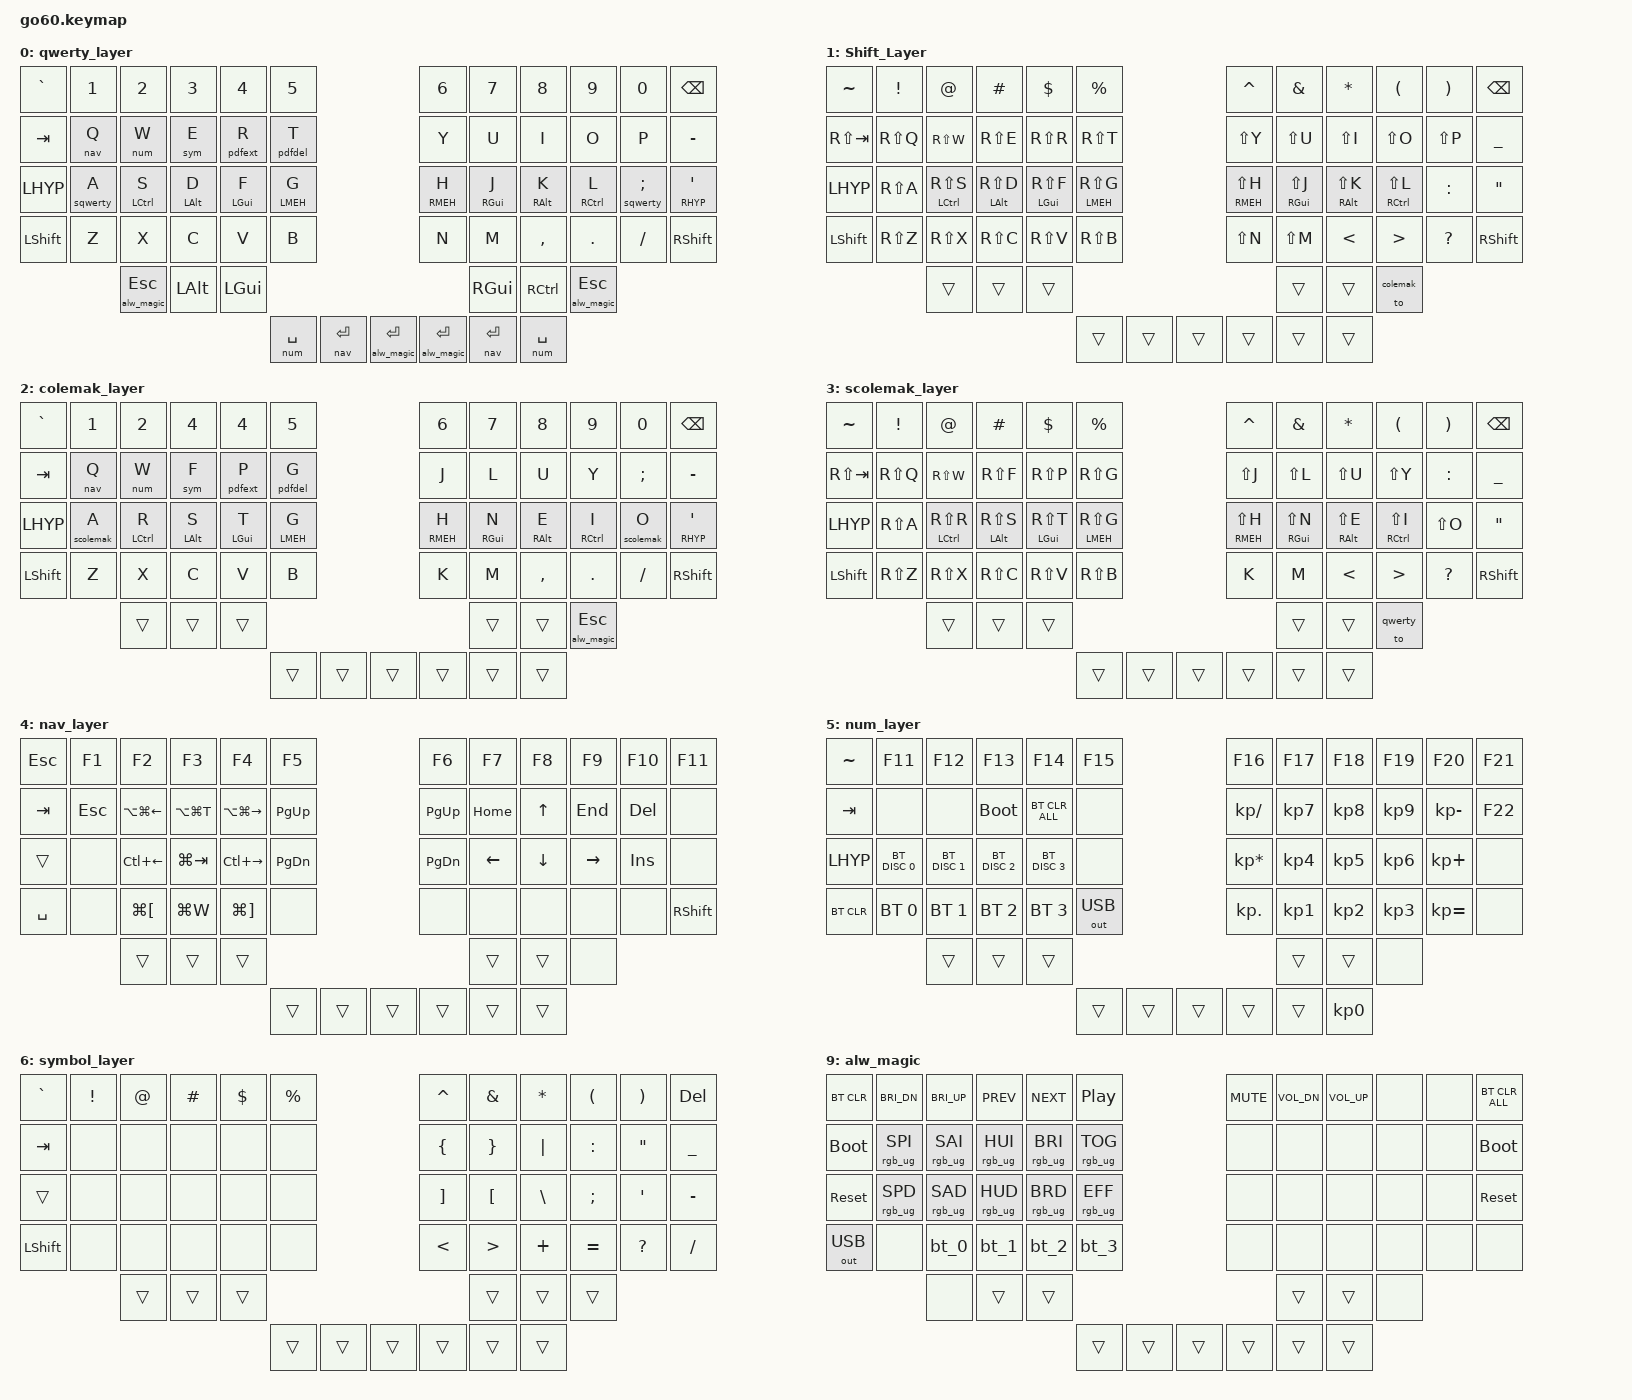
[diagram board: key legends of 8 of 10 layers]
/*
 * Copyright (c) 2020 The ZMK Contributors
 *
 * SPDX-License-Identifier: MIT
 */

#include <behaviors.dtsi>

#include <dt-bindings/zmk/bt.h>
#include <dt-bindings/zmk/ext_power.h>
#include <dt-bindings/zmk/keys.h>
#include <dt-bindings/zmk/outputs.h>
#include <dt-bindings/zmk/rgb.h>
#include <dt-bindings/zmk/input_transform.h>
#include <dt-bindings/zmk/pointing.h>

#include <input/processors.dtsi>
#include <zephyr/dt-bindings/input/input-event-codes.h>

// layers
#define LAYER_Base 9
#define LAYER_Keypad 10
#define LAYER_SymbolNav 11
#define LAYER_Magic 12
#define LAYER_Factory 0

//Layer Names Defines
#define qwerty 0
#define sqwerty 1
#define colemak 2
#define scolemak 3
#define nav 4
#define num 5
#define sym 6
#define pdfext 7
#define pdfdel 8
#define alw_magic 9



// custom modifier combinations
#define LHYP LS(LC(LA(LGUI)))
#define RHYP RS(RC(RA(RGUI)))
#define LMEH LS(LC(LALT))
#define RMEH RS(RC(RALT))

/ {
    combos {
        compatible = "zmk,combos";

        combo_tl1 {
            timeout-ms = <200>;
            key-positions = <36 37>;
            bindings = <&tog colemak>;
        };
        combo_tl2 {
            timeout-ms = <200>;
            key-positions = <36 38>;
            bindings = <&tog nav>;
        };
        combo_tl3 {
            timeout-ms = <200>;
            key-positions = <36 39>;
            bindings = <&tog num>;
        };
        combo_tl4 {
            timeout-ms = <200>;
            key-positions = <36 40>;
            bindings = <&tog sym>;
        };
        combo_tl5 {
            timeout-ms = <200>;
            key-positions = <36 41>;
            bindings = <&tog colemak>;
        };



        combo_tlr1 {
            timeout-ms = <200>;
            key-positions = <47 46>;
            bindings = <&tog colemak>;
        };
        combo_tlr2 {
            timeout-ms = <200>;
            key-positions = <47 45>;
            bindings = <&tog nav>;
        };
        combo_tlr3 {
            timeout-ms = <200>;
            key-positions = <47 44>;
            bindings = <&tog num>;
        };
        combo_tlr4 {
            timeout-ms = <200>;
            key-positions = <47 43>;
            bindings = <&tog sym>;
        };
        combo_tlr5 {
            timeout-ms = <200>;
            key-positions = <47 42>;
            bindings = <&tog colemak>;
        };



    };
};


/ {
    input_processors {
        zip_click_to_right_click_mapper: zip_click_to_right_click_mapper {
            compatible = "zmk,input-processor-code-mapper";
            #input-processor-cells = <0>;
            type = <INPUT_EV_KEY>;
            map = <INPUT_BTN_0 INPUT_BTN_1>;
        };
    };

    behaviors {

       gresc: grave_escape {
            compatible = "zmk,behavior-mod-morph";
            #binding-cells = <0>;
            bindings = <&kp ESC>, <&kp GRAVE>;
            mods = <(MOD_LGUI|MOD_LSFT|MOD_RGUI|MOD_RSFT)>;
                            };             
        hml: home_row_mod_left {
            compatible = "zmk,behavior-hold-tap";
            #binding-cells = <2>;
            flavor = "balanced";
            require-prior-idle-ms = <125>;
            tapping-term-ms = <300>;
            quick-tap-ms = <175>;
            bindings = <&kp>, <&kp>;
            hold-trigger-key-positions = <25 26 27 28 29>; // List of keys on the right side of the keyboard
            hold-trigger-on-release;
        };
        hmr: home_row_mod_right {
            compatible = "zmk,behavior-hold-tap";
            #binding-cells = <2>;
            flavor = "balanced";
            require-prior-idle-ms = <125>;
            tapping-term-ms = <300>;
            quick-tap-ms = <175>;
            bindings = <&kp>, <&kp>;
            hold-trigger-key-positions = <30 31 32 33 34>; // List of keys on the left side of the keyboard
            hold-trigger-on-release;
        };
        hmt: hyper_mod_tap {
            compatible = "zmk,behavior-hold-tap";
            #binding-cells = <2>;
            flavor = "balanced";
            require-prior-idle-ms = <125>;
            tapping-term-ms = <350>;
            quick-tap-ms = <175>;
            bindings = <&kp>, <&kp>;
            hold-trigger-key-positions = <35>; // List of keys on the Right side of the keyboard
            hold-trigger-on-release;
        };


        magic: magic {
            compatible = "zmk,behavior-hold-tap";
            #binding-cells = <2>;
            flavor = "tap-preferred";
            tapping-term-ms = <200>;
            bindings = <&mo>, <&rgb_ug_status_macro>;
        };

        keypad_td: keypad_td {
            compatible = "zmk,behavior-tap-dance";
            #binding-cells = <0>;
            tapping-term-ms = <200>;
            bindings = <&mo LAYER_Keypad>, <&to LAYER_Keypad>;
        };

        symbol_nav_td: symbol_nav_td {
            compatible = "zmk,behavior-tap-dance";
            #binding-cells = <0>;
            tapping-term-ms = <200>;
            bindings = <&mo LAYER_SymbolNav>, <&to LAYER_SymbolNav>;
        };

        bt_0: bt_0 {
            compatible = "zmk,behavior-tap-dance";
            #binding-cells = <0>;
            tapping-term-ms = <200>;
            bindings = <&bt_select_0>, <&bt BT_DISC 0>;
        };
        bt_1: bt_1 {
            compatible = "zmk,behavior-tap-dance";
            #binding-cells = <0>;
            tapping-term-ms = <200>;
            bindings = <&bt_select_1>, <&bt BT_DISC 1>;
        };
        bt_2: bt_2 {
            compatible = "zmk,behavior-tap-dance";
            #binding-cells = <0>;
            tapping-term-ms = <200>;
            bindings = <&bt_select_2>, <&bt BT_DISC 2>;
        };
        bt_3: bt_3 {
            compatible = "zmk,behavior-tap-dance";
            #binding-cells = <0>;
            tapping-term-ms = <200>;
            bindings = <&bt_select_3>, <&bt BT_DISC 3>;
        };
    };

    macros {
        rgb_ug_status_macro: rgb_ug_status_macro {
            compatible = "zmk,behavior-macro";
            #binding-cells = <0>;
            bindings = <&rgb_ug RGB_STATUS>;
        };

        bt_select_0: bt_select_0 {
            compatible = "zmk,behavior-macro";
            #binding-cells = <0>;
            bindings
                = <&out OUT_BLE>,
                  <&bt BT_SEL 0>;
        };
        bt_select_1: bt_select_1 {
            compatible = "zmk,behavior-macro";
            #binding-cells = <0>;
            bindings
                = <&out OUT_BLE>,
                  <&bt BT_SEL 1>;
        };
        bt_select_2: bt_select_2 {
            compatible = "zmk,behavior-macro";
            #binding-cells = <0>;
            bindings
                = <&out OUT_BLE>,
                  <&bt BT_SEL 2>;
        };
        bt_select_3: bt_select_3 {
            compatible = "zmk,behavior-macro";
            #binding-cells = <0>;
            bindings
                = <&out OUT_BLE>,
                  <&bt BT_SEL 3>;
        };
    };

    keymap {
        compatible = "zmk,keymap";
    qwerty_layer         {   bindings =<  
//          `                    1                    2                    3                    4                    5                                                                                                        6                    7                    8                    9                    0                  bksp         
        &kp GRAVE              &kp N1               &kp N2               &kp N3               &kp N4               &kp N5                                                                                                   &kp N6               &kp N7               &kp N8               &kp N9               &kp N0             &kp BSPC       
//         Tab                   Q                    W                    E                    R                    T                                                                                                        Y                    U                    I                    O                    P                    -          
         &kp TAB             &lt nav Q            &lt num W            &lt sym E          &lt pdfext R         &lt pdfdel T                                                                                                 &kp Y                &kp U                &kp I                &kp O                &kp P              &kp MINUS      
//        HYPER                  A                    S                    D                    F                    G                                                                                                        H                    J                    K                    L                    ;                   (')         
        &kp LHYP           &lt sqwerty A        &hml LCTRL S          &hml LALT D          &hml LGUI F          &hml LMEH G                                                                                              &hmr RMEH H          &hmr RGUI J          &hmr RALT K         &hmr RCTRL L       &lt sqwerty SEMI       &hmt RHYP SQT     
//        LSHIFT                 Z                    X                    C                    V                    B                                                                                                        N                    M                    ,                    .                    /                  RSHIFT       
        &kp LSHFT              &kp Z                &kp X                &kp C                &kp V                &kp B                                                                                                    &kp N                &kp M              &kp COMMA             &kp DOT             &kp FSLH             &kp RSHFT      
//                                                  Escape               LALT                 LGUI                                                                                                                                               RGUI                 RCtrl          Layer Magic / ESC                                            
                                            &lt alw_magic ESC        &kp LALT             &kp LGUI                                                                                                                                           &kp RGUI             &kp RCTRL        &lt alw_magic ESC                                            
//                                                                                                                 SPACE           Layer Nav / RET         LayerMagic           LayerMagic        Layer Nav / RET     Layer Num / SPACE                                                                                                           
                                                                                                               &lt num SPACE         &lt nav RET       &lt alw_magic RET    &lt alw_magic RET       &lt nav RET         &lt num SPACE                                                                                                             
          >;          
          };         

     Shift_Layer         {   bindings =<  
//          ~                    !                    @                    #                    $                    %                                                                                                        ^                    &                    *                    (                    )                  bksp         
        &kp TILDE            &kp EXCL               &kp AT             &kp POUND            &kp DLLR             &kp PRCNT                                                                                                &kp CARET            &kp AMPS             &kp ASTRK            &kp LPAR             &kp RPAR             &kp BSPC       
//      Shift Tab                Q                    W                    E                    R                    T                                                                                                        Y                    U                    I                    O                    P                    _          
       &kp RS(TAB)           &kp RS(Q)            &kp RS(W)            &kp RS(E)            &kp RS(R)            &kp RS(T)                                                                                                &kp LS(Y)            &kp LS(U)            &kp LS(I)            &kp LS(O)            &kp LS(P)            &kp UNDER      
//        HYPER                  A                    S                    D                    F                    G                                                                                                        H                    J                    K                    L                   (:)                  ( " )       
        &kp LHYP             &kp RS(A)        &hml LCTRL RS(S)      &hml LALT RS(D)      &hml LGUI RS(F)      &hml LMEH RS(G)                                                                                          &hmr RMEH LS(H)      &hmr RGUI LS(J)      &hmr RALT LS(K)     &hmr RCTRL LS(L)         &kp COLON             &kp DQT       
//        LSHIFT                 Z                    X                    C                    V                    B                                                                                                        N                    M                   (<)                  (>)                  (?)                 RSHIFT       
        &kp LSHFT            &kp RS(Z)            &kp RS(X)            &kp RS(C)            &kp RS(V)            &kp RS(B)                                                                                                &kp LS(N)            &kp LS(M)              &kp LT               &kp GT             &kp QMARK            &kp RSHFT      
//                                                  TRANS                TRANS                TRANS                                                                                                                                              TRANS                TRANS            Layer Colemak                                              
                                                  &trans               &trans               &trans                                                                                                                                             &trans               &trans            &to colemak                                               
//                                                                                                                 TRANS                TRANS                TRANS                TRANS                TRANS                TRANS                                                                                                                 
                                                                                                                   &trans               &trans               &trans               &trans               &trans               &trans                                                                                                                
          >;          
          };         

    colemak_layer        {   bindings =<  
//          `                    1                    2                    3                    4                    5                                                                                                        6                    7                    8                    9                    0                  bksp         
        &kp GRAVE              &kp N1               &kp N2               &kp N4               &kp N4               &kp N5                                                                                                   &kp N6               &kp N7               &kp N8               &kp N9               &kp N0             &kp BSPC       
//         Tab                   Q                    W                    F                    P                    G                                                                                                        J                    L                    U                    Y                    ;                    -          
         &kp TAB             &lt nav Q            &lt num W            &lt sym F          &lt pdfext P         &lt pdfdel G                                                                                                 &kp J                &kp L                &kp U                &kp Y              &kp SEMI             &kp MINUS      
//        HYPER                  A                    R                    S                    T                    D                                                                                                        H                    N                    E                    I                    O                   (')         
        &kp LHYP           &lt scolemak A       &hml LCTRL R          &hml LALT S          &hml LGUI T          &hml LMEH G                                                                                              &hmr RMEH H          &hmr RGUI N          &hmr RALT E         &hmr RCTRL I         &lt scolemak O       &hmt RHYP SQT     
//        LSHIFT                 Z                    X                    C                    V                    B                                                                                                        K                    M                    ,                    .                    /                  RSHIFT       
        &kp LSHFT              &kp Z                &kp X                &kp C                &kp V                &kp B                                                                                                    &kp K                &kp M              &kp COMMA             &kp DOT             &kp FSLH             &kp RSHFT      
//                                                  TRANS                TRANS                TRANS                                                                                                                                              TRANS                TRANS          Layer Magic / ESC                                            
                                                  &trans               &trans               &trans                                                                                                                                             &trans               &trans         &lt alw_magic ESC                                            
//                                                                                                                 TRANS                TRANS                TRANS                TRANS                TRANS                TRANS                                                                                                                 
                                                                                                                   &trans               &trans               &trans               &trans               &trans               &trans                                                                                                                
          >;          
          };         

   scolemak_layer        {   bindings =<  
//          ~                    1                    2                    3                    4                    5                                                                                                        6                    7                    8                    9                    0                  bksp         
        &kp TILDE            &kp EXCL               &kp AT             &kp POUND            &kp DLLR             &kp PRCNT                                                                                                &kp CARET            &kp AMPS             &kp ASTRK            &kp LPAR             &kp RPAR             &kp BSPC       
//      Shift Tab                Q                    W                    F                    P                    G                                                                                                        J                    L                    U                    Y                   (:)                   _          
       &kp RS(TAB)           &kp RS(Q)            &kp RS(W)            &kp RS(F)            &kp RS(P)            &kp RS(G)                                                                                                &kp LS(J)            &kp LS(L)            &kp LS(U)            &kp LS(Y)            &kp COLON            &kp UNDER      
//        HYPER                  A                    R                    S                    T                    D                                                                                                        H                    N                    E                    I                    O                   ( " )       
        &kp LHYP             &kp RS(A)        &hml LCTRL RS(R)      &hml LALT RS(S)      &hml LGUI RS(T)      &hml LMEH RS(G)                                                                                          &hmr RMEH LS(H)      &hmr RGUI LS(N)      &hmr RALT LS(E)     &hmr RCTRL LS(I)         &kp LS(O)             &kp DQT       
//        LSHIFT                 Z                    X                    C                    V                    B                                                                                                        K                    M                   (<)                  (>)                  (?)                 RSHIFT       
        &kp LSHFT            &kp RS(Z)            &kp RS(X)            &kp RS(C)            &kp RS(V)            &kp RS(B)                                                                                                  &kp K                &kp M                &kp LT               &kp GT             &kp QMARK            &kp RSHFT      
//                                                  TRANS                TRANS                TRANS                                                                                                                                              TRANS                TRANS            Layer Qwerty                                               
                                                  &trans               &trans               &trans                                                                                                                                             &trans               &trans             &to qwerty                                               
//                                                                                                                 TRANS                TRANS                TRANS                TRANS                TRANS                TRANS                                                                                                                 
                                                                                                                   &trans               &trans               &trans               &trans               &trans               &trans                                                                                                                
          >;          
          };         

      nav_layer          {   bindings =<  
//         Esc                   F1                   F2                   F3                   F4                   F5                                                                                                       F6                   F7                   F8                   F9                  F10                  F11         
         &kp ESC               &kp F1               &kp F2               &kp F3               &kp F4               &kp F5                                                                                                   &kp F6               &kp F7               &kp F8               &kp F9              &kp F10              &kp F11       
//         Tab                  ESC             Alt OS L Arrw          Alt OS T           Alt OS R Arrw            PG UP                                                                                                    PG UP                HOME               Up Arrow                END                  Del                              
         &kp TAB              &kp ESC         &kp LA(LG(LEFT))       &kp LA(LG(T))      &kp LA(LG(RIGHT))        &kp PG_UP                                                                                                &kp PG_UP            &kp HOME               &kp UP              &kp END              &kp DEL               &none        
//        TRANS                                  CTRL L ARRW             OS TAB            CTRL R ARRW             PG DN                                                                                                    PG DN              Left Arrow           Dwn Arrow           Right Arrow             Insert                            
          &trans               &none            &kp LC(LEFT)          &kp LG(TAB)         &kp LC(RIGHT)          &kp PG_DN                                                                                                &kp PG_DN            &kp LEFT             &kp DOWN             &kp RIGHT             &kp INS               &none        
//        Space                                     OS [                 OS W                 OS ]                 None                                                                                                     None                 None                 None                 None                 None                 RSHIFT       
        &kp SPACE              &none            &kp LG(LBKT)           &kp LG(W)          &kp LG(RBKT)             &none                                                                                                    &none                &none                &none                &none                &none              &kp RSHFT      
//                                                  TRANS                TRANS                TRANS                                                                                                                                              TRANS                TRANS                None                                                   
                                                  &trans               &trans               &trans                                                                                                                                             &trans               &trans               &none                                                  
//                                                                                                                 TRANS                TRANS                TRANS                TRANS                TRANS                TRANS                                                                                                                 
                                                                                                                   &trans               &trans               &trans               &trans               &trans               &trans                                                                                                                
          >;          
          };         

      num_layer          {   bindings =<  
//          ~                   F11                  F12                  F13                  F14                  F15                                                                                                      F16                  F17                  F18                  F19                  F20                  F21         
        &kp TILDE             &kp F11              &kp F12              &kp F13              &kp F14              &kp F15                                                                                                  &kp F16              &kp F17              &kp F18              &kp F19              &kp F20              &kp F21       
//         TAB                                                        Boot Loader           BTCLR ALL                                                                                                                       Num /                Num 7                Num 8                Num 9                Num -                 F22         
         &kp TAB               &none                &none             &bootloader         &bt BT_CLR_ALL           &none                                                                                                &kp KP_DIVIDE          &kp KP_N7            &kp KP_N8            &kp KP_N9          &kp KP_MINUS            &kp F22       
//        Hyper              BT0 DISC             BT1 DISC             BT2 DISC             BT3 DISC                                                                                                                        Num *                Num 4                Num 5                Num 6                Num +                             
        &kp LHYP           &bt BT_DISC 0        &bt BT_DISC 1        &bt BT_DISC 2        &bt BT_DISC 3            &none                                                                                               &kp KP_ASTERISK         &kp KP_N4            &kp KP_N5            &kp KP_N6           &kp KP_PLUS             &none        
//        BTCLR                 BT0                  BT1                  BT2                  BT3               USB-BT USB                                                                                                 Num .                Num 1                Num 2                Num 3               Num Ent                            
        &bt BT_CLR         &bt BT_SEL 0         &bt BT_SEL 1         &bt BT_SEL 2         &bt BT_SEL 3         &out OUT_USB                                                                                               &kp KP_DOT           &kp KP_N1            &kp KP_N2            &kp KP_N3          &kp KP_EQUAL             &none        
//                                                  TRANS                TRANS                TRANS                                                                                                                                              TRANS                TRANS                None                                                   
                                                  &trans               &trans               &trans                                                                                                                                             &trans               &trans               &none                                                  
//                                                                                                                 TRANS                TRANS                TRANS                TRANS                TRANS                Num 0                                                                                                                 
                                                                                                                   &trans               &trans               &trans               &trans               &trans             &kp KP_N0                                                                                                               
          >;          
          };         

    symbol_layer         {   bindings =<  
//          `                    !                    @                    #                    $                    %                                                                                                        ^                    &                    *                    (                    )                  Delete       
        &kp GRAVE            &kp EXCL               &kp AT             &kp HASH             &kp DLLR             &kp PRCNT                                                                                                &kp CARET            &kp AMPS             &kp ASTRK            &kp LPAR             &kp RPAR              &kp DEL       
//         Tab                                                                                                                                                                                                                {                    }                    |                    :                    "                    _          
         &kp TAB               &none                &none                &none                &none                &none                                                                                                  &kp LBRC             &kp RBRC             &kp PIPE             &kp COLON             &kp DQT             &kp UNDER      
//                                                                                                                                                                                                                            [                    ]                    \                    ;                   (')                   -          
          &trans               &none                &none                &none                &none                &none                                                                                                  &kp RBKT             &kp LBKT             &kp BSLH             &kp SEMI              &kp SQT             &kp MINUS      
//        LSHIFT                                                                                                                                                                                                              <                    >                    +                    =                    ?                    /          
        &kp LSHFT              &none                &none                &none                &none                &none                                                                                                    &kp LT               &kp GT             &kp PLUS             &kp EQUAL            &kp QMARK            &kp FSLH       
//                                                                                                                                                                                                                                                                                                                                                
                                                  &trans               &trans               &trans                                                                                                                                             &trans               &trans               &trans                                                 
//                                                                                                                                                                                                                                                                                                                                                
                                                                                                                   &trans               &trans               &trans               &trans               &trans               &trans                                                                                                                
          >;          
          };         

    pdf_extract          {   bindings =<  
//                                                                                                                                                                                                                                                                                                                                                
          &none                &none                &none                &none                &none                &none                                                                                                    &none                &none                &none                &none                &none                &none        
//                                                                                                                                                                                                                                               Num 7                Num 8                Num 9                                                  
          &none                &none                &none                &none                &none                &none                                                                                                    &none        &kp LS(LA(LC(KP_N7)))&kp LS(LA(LC(KP_N8)))&kp LS(LA(LC(KP_N9)))        &none                &none        
//                                                                                                                                                                                                                                               Num 4                Num 5                Num 6                                                  
          &none                &none                &none                &none                &none                &none                                                                                                    &none        &kp LS(LA(LC(KP_N4)))&kp LS(LA(LC(KP_N5)))&kp LS(LA(LC(KP_N6)))        &none                &none        
//                                                                                                                                                                                                                                               Num 1                Num 2                Num 3                                                  
          &none                &none                &none                &none                &none                &none                                                                                                    &none        &kp LS(LA(LC(KP_N1)))&kp LS(LA(LC(KP_N2)))&kp LS(LA(LC(KP_N3)))&kp LS(LA(LC(KP_EQUAL)))        &none        
//                                                                                                                                                                                                                                                                                                                                                
                                                  &trans               &trans               &trans                                                                                                                                             &trans               &trans               &none                                                  
//                                                                                                                                                                                                                                                                                                                                                
                                                                                                                   &trans               &trans               &trans               &trans               &trans       &kp LS(LA(LC(KP_N0)))                                                                                                         
          >;          
          };         

     pdf_delete          {   bindings =<  
//                                                                                                                                                                                                                                                                                                                                                
          &none                &none                &none                &none                &none                &none                                                                                                    &none                &none                &none                &none                &none                &none        
//                                                                                                                                                                                                                                               Num 7                Num 8                Num 9                                                  
          &none                &none                &none                &none                &none                &none                                                                                                    &none        &kp LS(LC(LG(KP_N7)))&kp LS(LC(LG(KP_N8)))&kp LS(LC(LG(KP_N9)))        &none                &none        
//                                                                                                                                                                                                                                               Num 4                Num 5                Num 6                                                  
          &none                &none                &none                &none                &none                &none                                                                                                    &none        &kp LS(LC(LG(KP_N4)))&kp LS(LC(LG(KP_N5)))&kp LS(LC(LG(KP_N6)))        &none                &none        
//                                                                                                                                                                                                                                               Num 1                Num 2                Num 3                                                  
          &none                &none                &none                &none                &none                &none                                                                                                    &none        &kp LS(LC(LG(KP_N1)))&kp LS(LC(LG(KP_N2)))&kp LS(LC(LG(KP_N3)))&kp LS(LC(LG(KP_EQUAL)))        &none        
//                                                                                                                                                                                                                                                                                                                                                
                                                  &trans               &trans               &trans                                                                                                                                             &trans               &trans               &none                                                  
//                                                                                                                                                                                                                                                                                                                                                
                                                                                                                   &trans               &trans               &trans               &trans               &trans       &kp LS(LC(LG(KP_N0)))                                                                                                         
          >;          
          };         

      alw_magic          {   bindings =<  
//        BT_CLR             Bright Dwn           Bright UP            Previous               Next             Play / Pause                                                                                                 Mute              Volume Down           Volume Up                                                    BT Clear All     
        &bt BT_CLR         &kp C_BRI_DN         &kp C_BRI_UP           &kp C_PREV           &kp C_NEXT           &kp C_PP                                                                                                 &kp C_MUTE         &kp C_VOL_DN         &kp C_VOL_UP             &none                &none            &bt BT_CLR_ALL   
//                         Speed Increase    Saturation Increase     Hue Increase      Brightness Increase       RGB Toggle                                                                                                                                                                                                                       
       &bootloader        &rgb_ug RGB_SPI      &rgb_ug RGB_SAI      &rgb_ug RGB_HUI      &rgb_ug RGB_BRI      &rgb_ug RGB_TOG                                                                                               &none                &none                &none                &none                &none             &bootloader     
//                         Speed Decrease    Saturation Decrease     Hue Decrease      Brightness Decrease     RGB Effect Fwd                                                                                                                                                                                                                     
        &sys_reset        &rgb_ug RGB_SPD      &rgb_ug RGB_SAD      &rgb_ug RGB_HUD      &rgb_ug RGB_BRD      &rgb_ug RGB_EFF                                                                                               &none                &none                &none                &none                &none              &sys_reset     
//      USB Output                                  BT_0                 BT_1                 BT_2                 BT_3                                                                                                                                                                                                                           
      &out OUT_USB             &none                &bt_0                &bt_1                &bt_2                &bt_3                                                                                                    &none                &none                &none                &none                &none                &none        
//                                                                                                                                                                                                                                                                                                                                                
                                                  &none                &trans               &trans                                                                                                                                             &trans               &trans               &none                                                  
//                                                                                                                                                                                                                                                                                                                                                
                                                                                                                   &trans               &trans               &trans               &trans               &trans               &trans                                                                                                                
          >;                                              
          };         

    };
};

&cirque_rh_listener {
    input-processors = <&zip_xy_scaler 3 1>;
    layer_4 {
        layers = <4>;
        input-processors = <&zip_xy_scaler 9 1>;
    };
};

&cirque_lh_listener {
    input-processors = <&zip_xy_to_scroll_mapper>, <&zip_xy_scaler 1 8>, <&zip_click_to_right_click_mapper>, <&zip_xy_transform (INPUT_TRANSFORM_Y_INVERT)>;
    layer_4 {
        layers = <4>;
        input-processors = <&zip_xy_scaler 3 1>;
    };
};
